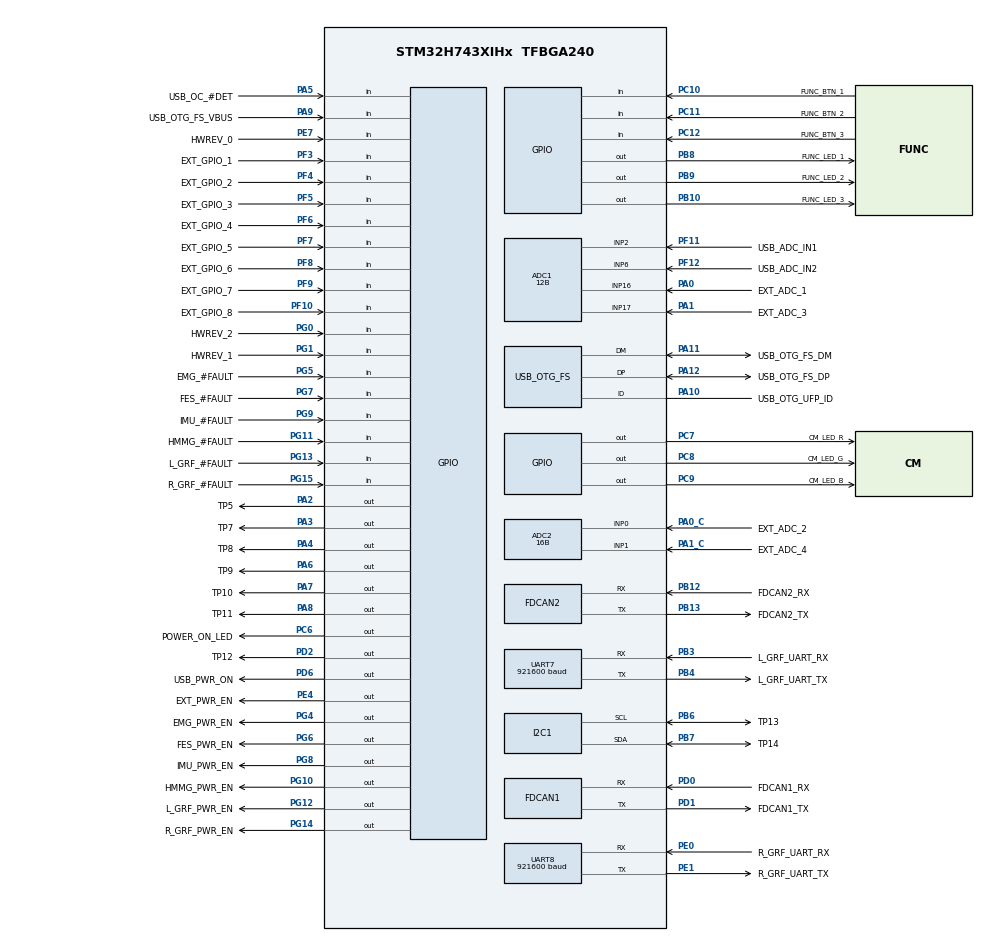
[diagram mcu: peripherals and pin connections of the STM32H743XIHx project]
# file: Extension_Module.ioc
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ADC1.Channel-0\#ChannelRegularConversion=ADC_CHANNEL_2
ADC1.Channel-1\#ChannelRegularConversion=ADC_CHANNEL_6
ADC1.Channel-4\#ChannelRegularConversion=ADC_CHANNEL_16
ADC1.Channel-5\#ChannelRegularConversion=ADC_CHANNEL_17
ADC1.ClockPrescaler=ADC_CLOCK_ASYNC_DIV4
ADC1.ContinuousConvMode=DISABLE
ADC1.ConversionDataManagement=ADC_CONVERSIONDATA_DMA_CIRCULAR
ADC1.EOCSelection=ADC_EOC_SEQ_CONV
ADC1.ExternalTrigConv=ADC_EXTERNALTRIG_T2_TRGO
ADC1.NbrOfConversion=4
ADC1.NbrOfConversionFlag=1
ADC1.OffsetNumber-0\#ChannelRegularConversion=ADC_OFFSET_NONE
ADC1.OffsetNumber-1\#ChannelRegularConversion=ADC_OFFSET_NONE
ADC1.OffsetNumber-4\#ChannelRegularConversion=ADC_OFFSET_NONE
ADC1.OffsetNumber-5\#ChannelRegularConversion=ADC_OFFSET_NONE
ADC1.OffsetSignedSaturation-0\#ChannelRegularConversion=DISABLE
ADC1.OffsetSignedSaturation-1\#ChannelRegularConversion=DISABLE
ADC1.Overrun=ADC_OVR_DATA_OVERWRITTEN
ADC1.Rank-0\#ChannelRegularConversion=1
ADC1.Rank-1\#ChannelRegularConversion=2
ADC1.Rank-4\#ChannelRegularConversion=3
ADC1.Rank-5\#ChannelRegularConversion=4
ADC1.Resolution=ADC_RESOLUTION_12B
ADC1.SamplingTime-0\#ChannelRegularConversion=ADC_SAMPLETIME_810CYCLES_5
ADC1.SamplingTime-1\#ChannelRegularConversion=ADC_SAMPLETIME_810CYCLES_5
ADC1.SamplingTime-4\#ChannelRegularConversion=ADC_SAMPLETIME_387CYCLES_5
ADC1.SamplingTime-5\#ChannelRegularConversion=ADC_SAMPLETIME_387CYCLES_5
ADC1.master=1
ADC2.Channel-0\#ChannelRegularConversion=ADC_CHANNEL_0
ADC2.Channel-1\#ChannelRegularConversion=ADC_CHANNEL_1
ADC2.ClockPrescaler=ADC_CLOCK_ASYNC_DIV4
ADC2.ContinuousConvMode=DISABLE
ADC2.ConversionDataManagement=ADC_CONVERSIONDATA_DMA_CIRCULAR
ADC2.EOCSelection=ADC_EOC_SEQ_CONV
ADC2.ExternalTrigConv=ADC_EXTERNALTRIG_T2_TRGO
ADC2.NbrOfConversion=2
ADC2.NbrOfConversionFlag=1
ADC2.OffsetNumber-0\#ChannelRegularConversion=ADC_OFFSET_NONE
ADC2.OffsetNumber-1\#ChannelRegularConversion=ADC_OFFSET_NONE
ADC2.OffsetSignedSaturation-0\#ChannelRegularConversion=DISABLE
ADC2.OffsetSignedSaturation-1\#ChannelRegularConversion=DISABLE
ADC2.Overrun=ADC_OVR_DATA_OVERWRITTEN
ADC2.Rank-0\#ChannelRegularConversion=1
ADC2.Rank-1\#ChannelRegularConversion=2
ADC2.Resolution=ADC_RESOLUTION_16B
ADC2.SamplingTime-0\#ChannelRegularConversion=ADC_SAMPLETIME_387CYCLES_5
ADC2.SamplingTime-1\#ChannelRegularConversion=ADC_SAMPLETIME_387CYCLES_5
CORTEX_M7.AccessPermission-Cortex_Memory_Protection_Unit_Region0_Settings=MPU_REGION_FULL_ACCESS
CORTEX_M7.AccessPermission-Cortex_Memory_Protection_Unit_Region1_Settings=MPU_REGION_FULL_ACCESS
CORTEX_M7.AccessPermission-Cortex_Memory_Protection_Unit_Region2_Settings=MPU_REGION_FULL_ACCESS
CORTEX_M7.BaseAddress-Cortex_Memory_Protection_Unit_Region0_Settings=0x30000000
CORTEX_M7.BaseAddress-Cortex_Memory_Protection_Unit_Region1_Settings=0x30040000
CORTEX_M7.BaseAddress-Cortex_Memory_Protection_Unit_Region2_Settings=0x38000000
CORTEX_M7.CPU_DCache=Enabled
CORTEX_M7.CPU_ICache=Enabled
CORTEX_M7.DisableExec-Cortex_Memory_Protection_Unit_Region0_Settings=MPU_INSTRUCTION_ACCESS_DISABLE
CORTEX_M7.DisableExec-Cortex_Memory_Protection_Unit_Region1_Settings=MPU_INSTRUCTION_ACCESS_DISABLE
CORTEX_M7.DisableExec-Cortex_Memory_Protection_Unit_Region2_Settings=MPU_INSTRUCTION_ACCESS_DISABLE
CORTEX_M7.Enable-Cortex_Memory_Protection_Unit_Region0_Settings=MPU_REGION_ENABLE
CORTEX_M7.Enable-Cortex_Memory_Protection_Unit_Region1_Settings=MPU_REGION_ENABLE
CORTEX_M7.Enable-Cortex_Memory_Protection_Unit_Region2_Settings=MPU_REGION_ENABLE
CORTEX_M7.IsBufferable-Cortex_Memory_Protection_Unit_Region0_Settings=MPU_ACCESS_NOT_BUFFERABLE
CORTEX_M7.IsCacheable-Cortex_Memory_Protection_Unit_Region0_Settings=MPU_ACCESS_NOT_CACHEABLE
CORTEX_M7.IsShareable-Cortex_Memory_Protection_Unit_Region0_Settings=MPU_ACCESS_SHAREABLE
CORTEX_M7.IsShareable-Cortex_Memory_Protection_Unit_Region1_Settings=MPU_ACCESS_SHAREABLE
CORTEX_M7.IsShareable-Cortex_Memory_Protection_Unit_Region2_Settings=MPU_ACCESS_SHAREABLE
CORTEX_M7.MPU_Control=MPU_HFNMI_PRIVDEF
CORTEX_M7.Size-Cortex_Memory_Protection_Unit_Region0_Settings=MPU_REGION_SIZE_256KB
CORTEX_M7.Size-Cortex_Memory_Protection_Unit_Region1_Settings=MPU_REGION_SIZE_32KB
CORTEX_M7.Size-Cortex_Memory_Protection_Unit_Region2_Settings=MPU_REGION_SIZE_64KB
CORTEX_M7.TypeExtField-Cortex_Memory_Protection_Unit_Region0_Settings=MPU_TEX_LEVEL1
CORTEX_M7.TypeExtField-Cortex_Memory_Protection_Unit_Region1_Settings=MPU_TEX_LEVEL1
CORTEX_M7.TypeExtField-Cortex_Memory_Protection_Unit_Region2_Settings=MPU_TEX_LEVEL1
Dma.ADC1.0.Direction=DMA_PERIPH_TO_MEMORY
Dma.ADC1.0.EventEnable=DISABLE
Dma.ADC1.0.FIFOMode=DMA_FIFOMODE_DISABLE
Dma.ADC1.0.Instance=DMA1_Stream0
Dma.ADC1.0.MemDataAlignment=DMA_MDATAALIGN_HALFWORD
Dma.ADC1.0.MemInc=DMA_MINC_ENABLE
Dma.ADC1.0.Mode=DMA_CIRCULAR
Dma.ADC1.0.PeriphDataAlignment=DMA_PDATAALIGN_HALFWORD
Dma.ADC1.0.PeriphInc=DMA_PINC_DISABLE
Dma.ADC1.0.Polarity=HAL_DMAMUX_REQ_GEN_RISING
Dma.ADC1.0.Priority=DMA_PRIORITY_LOW
Dma.ADC1.0.RequestNumber=1
Dma.ADC1.0.SignalID=NONE
Dma.ADC1.0.SyncEnable=DISABLE
Dma.ADC1.0.SyncPolarity=HAL_DMAMUX_SYNC_NO_EVENT
Dma.ADC1.0.SyncRequestNumber=1
Dma.ADC1.0.SyncSignalID=NONE
Dma.ADC2.3.Direction=DMA_PERIPH_TO_MEMORY
Dma.ADC2.3.EventEnable=DISABLE
Dma.ADC2.3.FIFOMode=DMA_FIFOMODE_DISABLE
Dma.ADC2.3.Instance=DMA1_Stream1
Dma.ADC2.3.MemDataAlignment=DMA_MDATAALIGN_HALFWORD
Dma.ADC2.3.MemInc=DMA_MINC_ENABLE
Dma.ADC2.3.Mode=DMA_CIRCULAR
Dma.ADC2.3.PeriphDataAlignment=DMA_PDATAALIGN_HALFWORD
Dma.ADC2.3.PeriphInc=DMA_PINC_DISABLE
Dma.ADC2.3.Polarity=HAL_DMAMUX_REQ_GEN_RISING
Dma.ADC2.3.Priority=DMA_PRIORITY_LOW
Dma.ADC2.3.RequestNumber=1
Dma.ADC2.3.SignalID=NONE
Dma.ADC2.3.SyncEnable=DISABLE
Dma.ADC2.3.SyncPolarity=HAL_DMAMUX_SYNC_NO_EVENT
Dma.ADC2.3.SyncRequestNumber=1
Dma.ADC2.3.SyncSignalID=NONE
Dma.Request0=ADC1
Dma.Request1=UART7_RX
Dma.Request2=UART8_RX
Dma.Request3=ADC2
Dma.UART7_RX.1.Direction=DMA_PERIPH_TO_MEMORY
Dma.UART7_RX.1.EventEnable=DISABLE
Dma.UART7_RX.1.FIFOMode=DMA_FIFOMODE_ENABLE
Dma.UART7_RX.1.FIFOThreshold=DMA_FIFO_THRESHOLD_1QUARTERFULL
Dma.UART7_RX.1.Instance=DMA1_Stream2
Dma.UART7_RX.1.MemBurst=DMA_MBURST_SINGLE
Dma.UART7_RX.1.MemDataAlignment=DMA_MDATAALIGN_BYTE
Dma.UART7_RX.1.MemInc=DMA_MINC_ENABLE
Dma.UART7_RX.1.Mode=DMA_CIRCULAR
Dma.UART7_RX.1.PeriphBurst=DMA_PBURST_SINGLE
Dma.UART7_RX.1.PeriphDataAlignment=DMA_PDATAALIGN_BYTE
Dma.UART7_RX.1.PeriphInc=DMA_PINC_DISABLE
Dma.UART7_RX.1.Polarity=HAL_DMAMUX_REQ_GEN_RISING
Dma.UART7_RX.1.Priority=DMA_PRIORITY_VERY_HIGH
Dma.UART7_RX.1.RequestNumber=1
Dma.UART7_RX.1.SignalID=NONE
Dma.UART7_RX.1.SyncEnable=DISABLE
Dma.UART7_RX.1.SyncPolarity=HAL_DMAMUX_SYNC_NO_EVENT
Dma.UART7_RX.1.SyncRequestNumber=1
Dma.UART7_RX.1.SyncSignalID=NONE
Dma.UART8_RX.2.Direction=DMA_PERIPH_TO_MEMORY
Dma.UART8_RX.2.EventEnable=DISABLE
Dma.UART8_RX.2.FIFOMode=DMA_FIFOMODE_ENABLE
Dma.UART8_RX.2.FIFOThreshold=DMA_FIFO_THRESHOLD_1QUARTERFULL
Dma.UART8_RX.2.Instance=DMA1_Stream3
Dma.UART8_RX.2.MemBurst=DMA_MBURST_SINGLE
Dma.UART8_RX.2.MemDataAlignment=DMA_MDATAALIGN_BYTE
Dma.UART8_RX.2.MemInc=DMA_MINC_ENABLE
Dma.UART8_RX.2.Mode=DMA_CIRCULAR
Dma.UART8_RX.2.PeriphBurst=DMA_PBURST_SINGLE
Dma.UART8_RX.2.PeriphDataAlignment=DMA_PDATAALIGN_BYTE
Dma.UART8_RX.2.PeriphInc=DMA_PINC_DISABLE
Dma.UART8_RX.2.Polarity=HAL_DMAMUX_REQ_GEN_RISING
Dma.UART8_RX.2.Priority=DMA_PRIORITY_VERY_HIGH
Dma.UART8_RX.2.RequestNumber=1
Dma.UART8_RX.2.SignalID=NONE
Dma.UART8_RX.2.SyncEnable=DISABLE
Dma.UART8_RX.2.SyncPolarity=HAL_DMAMUX_SYNC_NO_EVENT
Dma.UART8_RX.2.SyncRequestNumber=1
Dma.UART8_RX.2.SyncSignalID=NONE
FATFS._FS_RPATH=0
FATFS._MAX_SS=4096
FATFS._USE_LFN=2
FDCAN1.AutoRetransmission=ENABLE
FDCAN1.CalculateBaudRateNominal=1000000
FDCAN1.CalculateTimeBitNominal=1000
FDCAN1.CalculateTimeQuantumNominal=125.0
FDCAN1.DataSyncJumpWidth=4
FDCAN1.DataTimeSeg1=11
FDCAN1.DataTimeSeg2=4
FDCAN1.FrameFormat=FDCAN_FRAME_FD_BRS
FDCAN1.NominalPrescaler=10
FDCAN1.NominalSyncJumpWidth=2
FDCAN1.NominalTimeSeg1=5
FDCAN1.NominalTimeSeg2=2
FDCAN1.RxBufferSize=FDCAN_DATA_BYTES_64
FDCAN1.RxBuffersNbr=0
FDCAN1.RxFifo0ElmtSize=FDCAN_DATA_BYTES_64
FDCAN1.RxFifo0ElmtsNbr=20
FDCAN1.RxFifo1ElmtSize=FDCAN_DATA_BYTES_64
FDCAN1.RxFifo1ElmtsNbr=0
FDCAN1.StdFiltersNbr=28
FDCAN1.TransmitPause=ENABLE
FDCAN1.TxBuffersNbr=0
FDCAN1.TxElmtSize=FDCAN_DATA_BYTES_64
FDCAN1.TxEventsNbr=0
FDCAN1.TxFifoQueueElmtsNbr=32
FDCAN1.TxFifoQueueMode=FDCAN_TX_QUEUE_OPERATION
FDCAN2.AutoRetransmission=ENABLE
FDCAN2.CalculateBaudRateNominal=1000000
FDCAN2.CalculateTimeBitNominal=1000
FDCAN2.CalculateTimeQuantumNominal=125.0
FDCAN2.DataSyncJumpWidth=4
FDCAN2.DataTimeSeg1=11
FDCAN2.DataTimeSeg2=4
FDCAN2.FrameFormat=FDCAN_FRAME_FD_BRS
FDCAN2.MessageRAMOffset=1280
FDCAN2.NominalPrescaler=10
FDCAN2.NominalSyncJumpWidth=2
FDCAN2.NominalTimeSeg1=5
FDCAN2.NominalTimeSeg2=2
FDCAN2.RxBufferSize=FDCAN_DATA_BYTES_64
FDCAN2.RxFifo0ElmtSize=FDCAN_DATA_BYTES_64
FDCAN2.RxFifo0ElmtsNbr=20
FDCAN2.RxFifo1ElmtSize=FDCAN_DATA_BYTES_64
FDCAN2.StdFiltersNbr=28
FDCAN2.TransmitPause=ENABLE
FDCAN2.TxElmtSize=FDCAN_DATA_BYTES_64
FDCAN2.TxFifoQueueElmtsNbr=32
FDCAN2.TxFifoQueueMode=FDCAN_TX_QUEUE_OPERATION
FREERTOS.HEAP_NUMBER=4
FREERTOS.Tasks01=DefaultTask,8,128,StartDefaultTask,Default,NULL,Dynamic,NULL,NULL;UserTask,54,8192,StartUserTask,As weak,NULL,Dynamic,NULL,NULL;StartupTask,55,128,StartStartupTask,As weak,NULL,Dynamic,NULL,NULL
FREERTOS.configCHECK_FOR_STACK_OVERFLOW=2
FREERTOS.configENABLE_FPU=1
FREERTOS.configTOTAL_HEAP_SIZE=131072
FREERTOS.configUSE_NEWLIB_REENTRANT=1
I2C1.Timing=0x307075B1
Mcu.Family=STM32H7
Mcu.Name=STM32H743XIHx
Mcu.Package=TFBGA240
NVIC.ADC_IRQn=true\:5\:0\:false\:false\:true\:true\:true\:true\:true
NVIC.DMA1_Stream0_IRQn=true\:5\:0\:true\:false\:true\:true\:false\:true\:true
NVIC.DMA1_Stream1_IRQn=true\:5\:0\:true\:false\:true\:true\:false\:true\:true
NVIC.DMA1_Stream2_IRQn=true\:5\:0\:true\:false\:true\:true\:false\:true\:true
NVIC.DMA1_Stream3_IRQn=true\:5\:0\:true\:false\:true\:false\:false\:true\:true
NVIC.FDCAN1_IT0_IRQn=true\:5\:0\:true\:false\:true\:true\:true\:true\:true
NVIC.FDCAN1_IT1_IRQn=true\:5\:0\:false\:false\:true\:true\:true\:true\:true
NVIC.FDCAN2_IT0_IRQn=true\:5\:0\:false\:false\:true\:true\:true\:true\:true
NVIC.FDCAN2_IT1_IRQn=true\:5\:0\:false\:false\:true\:true\:true\:true\:true
NVIC.PriorityGroup=NVIC_PRIORITYGROUP_4
NVIC.TIM1_UP_IRQn=true\:15\:0\:false\:false\:true\:false\:false\:true\:true
NVIC.TimeBase=TIM1_UP_IRQn
NVIC.TimeBaseIP=TIM1
NVIC.UART7_IRQn=true\:5\:0\:false\:false\:true\:true\:true\:true\:true
NVIC.UART8_IRQn=true\:5\:0\:false\:false\:true\:true\:true\:true\:true
PA0.GPIO_Label=EXT_ADC_1
PA0.Mode=IN16-Single-Ended
PA0.Signal=ADC1_INP16
PA0_C.GPIO_Label=EXT_ADC_2
PA0_C.Signal=ADCx_INP0
PA1.GPIO_Label=EXT_ADC_3
PA1.Mode=IN17-Single-Ended
PA1.Signal=ADC1_INP17
PA10.GPIO_Label=USB_OTG_UFP_ID
PA10.Mode=OTG/Dual_Role_Device
PA10.Signal=USB_OTG_FS_ID
PA11.GPIO_Label=USB_OTG_FS_DM
PA11.GPIO_PuPd=GPIO_NOPULL
PA11.GPIO_Speed=GPIO_SPEED_FREQ_VERY_HIGH
PA11.Mode=OTG/Dual_Role_Device
PA11.Signal=USB_OTG_FS_DM
PA12.GPIO_Label=USB_OTG_FS_DP
PA12.GPIO_PuPd=GPIO_NOPULL
PA12.GPIO_Speed=GPIO_SPEED_FREQ_VERY_HIGH
PA12.Mode=OTG/Dual_Role_Device
PA12.Signal=USB_OTG_FS_DP
PA13\ (JTMS/SWDIO).GPIO_Label=DEBUG_SWDIO
PA13\ (JTMS/SWDIO).Mode=Serial_Wire
PA13\ (JTMS/SWDIO).Signal=DEBUG_JTMS-SWDIO
PA14\ (JTCK/SWCLK).GPIO_Label=DEBUG_SWCLK
PA14\ (JTCK/SWCLK).Mode=Serial_Wire
PA14\ (JTCK/SWCLK).Signal=DEBUG_JTCK-SWCLK
PA1_C.GPIO_Label=EXT_ADC_4
PA1_C.Signal=ADCx_INP1
PA2.GPIO_Label=TP5
PA2.GPIO_PuPd=GPIO_PULLDOWN
PA2.Signal=GPIO_Output
PA3.GPIO_Label=TP7
PA3.GPIO_PuPd=GPIO_PULLDOWN
PA3.Signal=GPIO_Output
PA4.GPIO_Label=TP8
PA4.Signal=GPIO_Output
PA5.GPIO_Label=USB_OC_\#DET
PA5.GPIO_PuPd=GPIO_NOPULL
PA5.Signal=GPIO_Input
PA6.GPIO_Label=TP9
PA6.GPIO_PuPd=GPIO_PULLDOWN
PA6.Signal=GPIO_Output
PA7.GPIO_Label=TP10
PA7.GPIO_PuPd=GPIO_PULLDOWN
PA7.Signal=GPIO_Output
PA8.GPIO_Label=TP11
PA8.GPIO_PuPd=GPIO_PULLDOWN
PA8.Signal=GPIO_Output
PA9.GPIO_Label=USB_OTG_FS_VBUS
PA9.GPIO_PuPd=GPIO_PULLUP
PA9.Signal=GPIO_Input
PB10.GPIO_Label=FUNC_LED_3
PB10.Signal=GPIO_Output
PB12.GPIO_Label=FDCAN2_RX
PB12.Mode=FDCAN_Activate
PB12.Signal=FDCAN2_RX
PB13.GPIO_Label=FDCAN2_TX
PB13.Mode=FDCAN_Activate
PB13.Signal=FDCAN2_TX
PB3\ (JTDO/TRACESWO).GPIO_Label=L_GRF_UART_RX
PB3\ (JTDO/TRACESWO).Mode=Asynchronous
PB3\ (JTDO/TRACESWO).Signal=UART7_RX
PB4\ (NJTRST).GPIO_Label=L_GRF_UART_TX
PB4\ (NJTRST).Mode=Asynchronous
PB4\ (NJTRST).Signal=UART7_TX
PB6.GPIO_Label=TP13
PB6.Mode=I2C
PB6.Signal=I2C1_SCL
PB7.GPIO_Label=TP14
PB7.Mode=I2C
PB7.Signal=I2C1_SDA
PB8.GPIO_Label=FUNC_LED_1
PB8.Signal=GPIO_Output
PB9.GPIO_Label=FUNC_LED_2
PB9.Signal=GPIO_Output
PC10.GPIO_Label=FUNC_BTN_1
PC10.Signal=GPIO_Input
PC11.GPIO_Label=FUNC_BTN_2
PC11.Signal=GPIO_Input
PC12.GPIO_Label=FUNC_BTN_3
PC12.Signal=GPIO_Input
PC14-OSC32_IN\ (OSC32_IN).Mode=LSE-External-Oscillator
PC14-OSC32_IN\ (OSC32_IN).Signal=RCC_OSC32_IN
PC15-OSC32_OUT\ (OSC32_OUT).Mode=LSE-External-Oscillator
PC15-OSC32_OUT\ (OSC32_OUT).Signal=RCC_OSC32_OUT
PC6.GPIO_Label=POWER_ON_LED
PC6.Signal=GPIO_Output
PC7.GPIO_Label=CM_LED_R
PC7.Signal=GPIO_Output
PC8.GPIO_Label=CM_LED_G
PC8.Signal=GPIO_Output
PC9.GPIO_Label=CM_LED_B
PC9.Signal=GPIO_Output
PD0.GPIO_Label=FDCAN1_RX
PD0.Mode=FDCAN_Activate
PD0.Signal=FDCAN1_RX
PD1.GPIO_Label=FDCAN1_TX
PD1.Mode=FDCAN_Activate
PD1.Signal=FDCAN1_TX
PD2.GPIO_Label=TP12
PD2.GPIO_PuPd=GPIO_PULLDOWN
PD2.Signal=GPIO_Output
PD6.GPIO_Label=USB_PWR_ON
PD6.GPIO_PuPd=GPIO_PULLUP
PD6.GPIO_Speed=GPIO_SPEED_FREQ_VERY_HIGH
PD6.Signal=GPIO_Output
PE0.GPIO_Label=R_GRF_UART_RX
PE0.Mode=Asynchronous
PE0.Signal=UART8_RX
PE1.GPIO_Label=R_GRF_UART_TX
PE1.Mode=Asynchronous
PE1.Signal=UART8_TX
PE4.GPIO_Label=EXT_PWR_EN
PE4.Signal=GPIO_Output
PE7.GPIO_Label=HWREV_0
PE7.Signal=GPIO_Input
PF10.GPIO_Label=EXT_GPIO_8
PF10.GPIO_PuPd=GPIO_NOPULL
PF10.Signal=GPIO_Input
PF11.GPIO_Label=USB_ADC_IN1
PF11.Mode=IN2-Single-Ended
PF11.Signal=ADC1_INP2
PF12.GPIO_Label=USB_ADC_IN2
PF12.Mode=IN6-Single-Ended
PF12.Signal=ADC1_INP6
PF3.GPIO_Label=EXT_GPIO_1
PF3.GPIO_PuPd=GPIO_NOPULL
PF3.Signal=GPIO_Input
PF4.GPIO_Label=EXT_GPIO_2
PF4.GPIO_PuPd=GPIO_NOPULL
PF4.Signal=GPIO_Input
PF5.GPIO_Label=EXT_GPIO_3
PF5.GPIO_PuPd=GPIO_NOPULL
PF5.Signal=GPIO_Input
PF6.GPIO_Label=EXT_GPIO_4
PF6.GPIO_PuPd=GPIO_NOPULL
PF6.Signal=GPIO_Input
PF7.GPIO_Label=EXT_GPIO_5
PF7.GPIO_PuPd=GPIO_NOPULL
PF7.Signal=GPIO_Input
PF8.GPIO_Label=EXT_GPIO_6
PF8.GPIO_PuPd=GPIO_NOPULL
PF8.Signal=GPIO_Input
PF9.GPIO_Label=EXT_GPIO_7
PF9.GPIO_PuPd=GPIO_NOPULL
PF9.Signal=GPIO_Input
PG0.GPIO_Label=HWREV_2
PG0.Signal=GPIO_Input
PG1.GPIO_Label=HWREV_1
PG1.Signal=GPIO_Input
PG10.GPIO_Label=HMMG_PWR_EN
PG10.Signal=GPIO_Output
PG11.GPIO_Label=HMMG_\#FAULT
PG11.Signal=GPIO_Input
PG12.GPIO_Label=L_GRF_PWR_EN
PG12.Signal=GPIO_Output
PG13.GPIO_Label=L_GRF_\#FAULT
PG13.Signal=GPIO_Input
PG14.GPIO_Label=R_GRF_PWR_EN
PG14.Signal=GPIO_Output
PG15.GPIO_Label=R_GRF_\#FAULT
PG15.Signal=GPIO_Input
PG4.GPIO_Label=EMG_PWR_EN
PG4.Signal=GPIO_Output
PG5.GPIO_Label=EMG_\#FAULT
PG5.Signal=GPIO_Input
PG6.GPIO_Label=FES_PWR_EN
PG6.Signal=GPIO_Output
PG7.GPIO_Label=FES_\#FAULT
PG7.Signal=GPIO_Input
PG8.GPIO_Label=IMU_PWR_EN
PG8.Signal=GPIO_Output
PG9.GPIO_Label=IMU_\#FAULT
PG9.Signal=GPIO_Input
PH0-OSC_IN\ (PH0).Mode=HSE-External-Oscillator
PH0-OSC_IN\ (PH0).Signal=RCC_OSC_IN
PH1-OSC_OUT\ (PH1).Mode=HSE-External-Oscillator
PH1-OSC_OUT\ (PH1).Signal=RCC_OSC_OUT
ProjectManager.HeapSize=0x2000
ProjectManager.StackSize=0x2000
ProjectManager.TargetToolchain=CMake
RCC.ADCFreq_Value=80000000
RCC.APB1Freq_Value=120000000
RCC.APB2Freq_Value=120000000
RCC.APB3Freq_Value=120000000
RCC.APB4Freq_Value=120000000
RCC.CKPERSourceSelection=RCC_CLKPSOURCE_HSE
RCC.CortexFreq_Value=480000000
RCC.D1PPRE=RCC_APB3_DIV2
RCC.D2PPRE1=RCC_APB1_DIV2
RCC.D2PPRE2=RCC_APB2_DIV2
RCC.D3PPRE=RCC_APB4_DIV2
RCC.DIVM1=5
RCC.DIVM2=5
RCC.DIVM3=5
RCC.DIVN1=192
RCC.DIVN2=80
RCC.DIVN3=192
RCC.DIVP2=5
RCC.DIVQ1=12
RCC.DIVQ3=20
RCC.DIVR2=1
RCC.DIVR3=10
RCC.HCLKFreq_Value=240000000
RCC.HPRE=RCC_HCLK_DIV2
RCC.PLL1_VCO_SEL-AdvancedSettings=RCC_PLL1VCOMEDIUM
RCC.PLL2FRACN=0
RCC.PLL2_VCI_Range-AdvancedSettings=RCC_PLL2VCIRANGE_1
RCC.PLL3_VCO_SEL-AdvancedSettings=RCC_PLL3VCOMEDIUM
RCC.PLLFRACN=0
RCC.PLLSourceVirtual=RCC_PLLSOURCE_HSE
RCC.SYSCLKFreq_VALUE=480000000
RCC.SYSCLKSource=RCC_SYSCLKSOURCE_PLLCLK
RCC.SupplySource=PWR_LDO_SUPPLY
RCC.USBCLockSelection=RCC_USBCLKSOURCE_HSI48
RCC.USBFreq_Value=48000000
SH.ADCx_INP0.0=ADC2_INP0,IN0-Single-Ended
SH.ADCx_INP1.0=ADC2_INP1,IN1-Single-Ended
TIM2.AutoReloadPreload=TIM_AUTORELOAD_PRELOAD_ENABLE
TIM2.Period=100-1
TIM2.Prescaler=240-1
TIM2.TIM_MasterOutputTrigger=TIM_TRGO_UPDATE
UART7.BaudRate=921600
UART7.FIFOMode=FIFOMODE_ENABLE
UART7.OverrunDisableParam=UART_ADVFEATURE_OVERRUN_ENABLE
UART7.RXFIFOThreshold=RXFIFO_THRESHOLD_1QUARTERFULL
UART7.TXFIFOThreshold=TXFIFO_THRESHOLD_1QUARTERFULL
UART8.BaudRate=921600
UART8.FIFOMode=FIFOMODE_ENABLE
UART8.OverrunDisableParam=UART_ADVFEATURE_OVERRUN_ENABLE
UART8.RXFIFOThreshold=RXFIFO_THRESHOLD_1QUARTERFULL
UART8.TXFIFOThreshold=TXFIFO_THRESHOLD_1QUARTERFULL
VP_FATFS_VS_Generic.Mode=User_defined
VP_FREERTOS_VS_CMSIS_V2.Mode=CMSIS_V2
VP_MEMORYMAP_VS_MEMORYMAP.Mode=CurAppReg
VP_SYS_VS_tim1.Mode=TIM1
VP_TIM2_VS_ClockSourceINT.Mode=Internal
board=custom

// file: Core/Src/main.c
/* USER CODE BEGIN Header */
/**
  ******************************************************************************
  * @file           : main.c
  * @brief          : Main program body
  ******************************************************************************
  * @attention
  *
  * Copyright (c) 2025 STMicroelectronics.
  * All rights reserved.
  *
  * This software is licensed under terms that can be found in the LICENSE file
  * in the root directory of this software component.
  * If no LICENSE file comes with this software, it is provided AS-IS.
  *
  ******************************************************************************
  */
/* USER CODE END Header */
#include "main.h"
#include "cmsis_os.h"
#include "fatfs.h"

ADC_HandleTypeDef hadc1;
ADC_HandleTypeDef hadc2;
DMA_HandleTypeDef hdma_adc1;
DMA_HandleTypeDef hdma_adc2;

FDCAN_HandleTypeDef hfdcan1;
FDCAN_HandleTypeDef hfdcan2;

I2C_HandleTypeDef hi2c1;

TIM_HandleTypeDef htim2;

UART_HandleTypeDef huart7;
UART_HandleTypeDef huart8;
DMA_HandleTypeDef hdma_uart7_rx;
DMA_HandleTypeDef hdma_uart8_rx;

/* Definitions for DefaultTask */
osThreadId_t DefaultTaskHandle;
const osThreadAttr_t DefaultTask_attributes = {
  .name = "DefaultTask",
  .stack_size = 128 * 4,
  .priority = (osPriority_t) osPriorityLow,
};
/* Definitions for UserTask */
osThreadId_t UserTaskHandle;
const osThreadAttr_t UserTask_attributes = {
  .name = "UserTask",
  .stack_size = 8192 * 4,
  .priority = (osPriority_t) osPriorityRealtime6,
};
/* Definitions for StartupTask */
osThreadId_t StartupTaskHandle;
const osThreadAttr_t StartupTask_attributes = {
  .name = "StartupTask",
  .stack_size = 128 * 4,
  .priority = (osPriority_t) osPriorityRealtime7,
};

void SystemClock_Config(void);
void PeriphCommonClock_Config(void);
static void MPU_Config(void);
static void MX_GPIO_Init(void);
static void MX_DMA_Init(void);
static void MX_I2C1_Init(void);
static void MX_UART7_Init(void);
static void MX_UART8_Init(void);
static void MX_FDCAN1_Init(void);
static void MX_USB_OTG_FS_USB_Init(void);
static void MX_ADC1_Init(void);
static void MX_ADC2_Init(void);
static void MX_FDCAN2_Init(void);
static void MX_TIM2_Init(void);
void StartDefaultTask(void *argument);
void StartUserTask(void *argument);
void StartStartupTask(void *argument);

/* USER CODE BEGIN 0 */
// static AGRBStatusDef _debug_adc_assign;
// static AGRBStatusDef _debug_uart7_status;
// static AGRBStatusDef _debug_uart8_status;
// TaskUSBControlTask_Init_t usbControlInitStruct;
/* USER CODE END 0 */

int main(void)
{

  /* MPU Configuration--------------------------------------------------------*/
  MPU_Config();

  /* Enable the CPU Cache */

  /* Enable I-Cache---------------------------------------------------------*/
  SCB_EnableICache();

  /* Enable D-Cache---------------------------------------------------------*/
  SCB_EnableDCache();

  /* MCU Configuration--------------------------------------------------------*/

  /* Reset of all peripherals, Initializes the Flash interface and the Systick. */
  HAL_Init();

  /* Configure the system clock */
  SystemClock_Config();

  /* Configure the peripherals common clocks */
  PeriphCommonClock_Config();

  /* Initialize all configured peripherals */
  MX_GPIO_Init();
  MX_DMA_Init();
  MX_I2C1_Init();
  MX_UART7_Init();
  MX_UART8_Init();
  MX_FATFS_Init();
  MX_FDCAN1_Init();
  MX_USB_OTG_FS_USB_Init();
  MX_ADC1_Init();
  MX_ADC2_Init();
  MX_FDCAN2_Init();
  MX_TIM2_Init();

  /* Init scheduler */
  osKernelInitialize();

  /* Create the thread(s) */
  /* creation of DefaultTask */
  DefaultTaskHandle = osThreadNew(StartDefaultTask, NULL, &DefaultTask_attributes);

  /* creation of UserTask */
  UserTaskHandle = osThreadNew(StartUserTask, NULL, &UserTask_attributes);

  /* creation of StartupTask */
  StartupTaskHandle = osThreadNew(StartStartupTask, NULL, &StartupTask_attributes);

  /* USER CODE BEGIN RTOS_THREADS */
  /* add threads, ... */

  /* [CRITICAL] UserTask Priority Override ⭐ KING
   * - IOC 설정값(Realtime4)을 Realtime6으로 상향
   * - 제어 공학적 원칙: Main Control Loop가 최우선
   * - FDCAN Rx Task(Realtime4)보다 높아야 함
   */
  osThreadSetPriority(UserTaskHandle, osPriorityRealtime6);

  osThreadSuspend(DefaultTaskHandle);
  osThreadSuspend(UserTaskHandle);
  /* USER CODE END RTOS_THREADS */

  /* Start scheduler */
  osKernelStart();

  /* We should never get here as control is now taken by the scheduler */

  /* Infinite loop */
  while (1)
  {

  }
}

void SystemClock_Config(void)
{
  RCC_OscInitTypeDef RCC_OscInitStruct = {0};
  RCC_ClkInitTypeDef RCC_ClkInitStruct = {0};

  /** Supply configuration update enable
  */
  HAL_PWREx_ConfigSupply(PWR_LDO_SUPPLY);

  /** Configure the main internal regulator output voltage
  */
  __HAL_PWR_VOLTAGESCALING_CONFIG(PWR_REGULATOR_VOLTAGE_SCALE0);

  while(!__HAL_PWR_GET_FLAG(PWR_FLAG_VOSRDY)) {}

  /** Initializes the RCC Oscillators according to the specified parameters
  * in the RCC_OscInitTypeDef structure.
  */
  RCC_OscInitStruct.OscillatorType = RCC_OSCILLATORTYPE_HSI48|RCC_OSCILLATORTYPE_HSE;
  RCC_OscInitStruct.HSEState = RCC_HSE_ON;
  RCC_OscInitStruct.HSI48State = RCC_HSI48_ON;
  RCC_OscInitStruct.PLL.PLLState = RCC_PLL_ON;
  RCC_OscInitStruct.PLL.PLLSource = RCC_PLLSOURCE_HSE;
  RCC_OscInitStruct.PLL.PLLM = 5;
  RCC_OscInitStruct.PLL.PLLN = 192;
  RCC_OscInitStruct.PLL.PLLP = 2;
  RCC_OscInitStruct.PLL.PLLQ = 12;
  RCC_OscInitStruct.PLL.PLLR = 2;
  RCC_OscInitStruct.PLL.PLLRGE = RCC_PLL1VCIRANGE_2;
  RCC_OscInitStruct.PLL.PLLVCOSEL = RCC_PLL1VCOWIDE;
  RCC_OscInitStruct.PLL.PLLFRACN = 0;
  if (HAL_RCC_OscConfig(&RCC_OscInitStruct) != HAL_OK)
  {
    Error_Handler();
  }

  /** Initializes the CPU, AHB and APB buses clocks
  */
  RCC_ClkInitStruct.ClockType = RCC_CLOCKTYPE_HCLK|RCC_CLOCKTYPE_SYSCLK
                              |RCC_CLOCKTYPE_PCLK1|RCC_CLOCKTYPE_PCLK2
                              |RCC_CLOCKTYPE_D3PCLK1|RCC_CLOCKTYPE_D1PCLK1;
  RCC_ClkInitStruct.SYSCLKSource = RCC_SYSCLKSOURCE_PLLCLK;
  RCC_ClkInitStruct.SYSCLKDivider = RCC_SYSCLK_DIV1;
  RCC_ClkInitStruct.AHBCLKDivider = RCC_HCLK_DIV2;
  RCC_ClkInitStruct.APB3CLKDivider = RCC_APB3_DIV2;
  RCC_ClkInitStruct.APB1CLKDivider = RCC_APB1_DIV2;
  RCC_ClkInitStruct.APB2CLKDivider = RCC_APB2_DIV2;
  RCC_ClkInitStruct.APB4CLKDivider = RCC_APB4_DIV2;

  if (HAL_RCC_ClockConfig(&RCC_ClkInitStruct, FLASH_LATENCY_4) != HAL_OK)
  {
    Error_Handler();
  }
}

void PeriphCommonClock_Config(void)
{
  RCC_PeriphCLKInitTypeDef PeriphClkInitStruct = {0};

  /** Initializes the peripherals clock
  */
  PeriphClkInitStruct.PeriphClockSelection = RCC_PERIPHCLK_ADC;
  PeriphClkInitStruct.PLL2.PLL2M = 5;
  PeriphClkInitStruct.PLL2.PLL2N = 80;
  PeriphClkInitStruct.PLL2.PLL2P = 5;
  PeriphClkInitStruct.PLL2.PLL2Q = 2;
  PeriphClkInitStruct.PLL2.PLL2R = 1;
  PeriphClkInitStruct.PLL2.PLL2RGE = RCC_PLL2VCIRANGE_2;
  PeriphClkInitStruct.PLL2.PLL2VCOSEL = RCC_PLL2VCOWIDE;
  PeriphClkInitStruct.PLL2.PLL2FRACN = 0;
  PeriphClkInitStruct.AdcClockSelection = RCC_ADCCLKSOURCE_PLL2;
  if (HAL_RCCEx_PeriphCLKConfig(&PeriphClkInitStruct) != HAL_OK)
  {
    Error_Handler();
  }
}

static void MX_ADC1_Init(void)
{

  ADC_MultiModeTypeDef multimode = {0};
  ADC_ChannelConfTypeDef sConfig = {0};

  /** Common config
  */
  hadc1.Instance = ADC1;
  hadc1.Init.ClockPrescaler = ADC_CLOCK_ASYNC_DIV4;
  hadc1.Init.Resolution = ADC_RESOLUTION_12B;
  hadc1.Init.ScanConvMode = ADC_SCAN_ENABLE;
  hadc1.Init.EOCSelection = ADC_EOC_SEQ_CONV;
  hadc1.Init.LowPowerAutoWait = DISABLE;
  hadc1.Init.ContinuousConvMode = DISABLE;
  hadc1.Init.NbrOfConversion = 4;
  hadc1.Init.DiscontinuousConvMode = DISABLE;
  hadc1.Init.ExternalTrigConv = ADC_EXTERNALTRIG_T2_TRGO;
  hadc1.Init.ExternalTrigConvEdge = ADC_EXTERNALTRIGCONVEDGE_RISING;
  hadc1.Init.ConversionDataManagement = ADC_CONVERSIONDATA_DMA_CIRCULAR;
  hadc1.Init.Overrun = ADC_OVR_DATA_OVERWRITTEN;
  hadc1.Init.LeftBitShift = ADC_LEFTBITSHIFT_NONE;
  hadc1.Init.OversamplingMode = DISABLE;
  hadc1.Init.Oversampling.Ratio = 1;
  if (HAL_ADC_Init(&hadc1) != HAL_OK)
  {
    Error_Handler();
  }

  /** Configure the ADC multi-mode
  */
  multimode.Mode = ADC_MODE_INDEPENDENT;
  if (HAL_ADCEx_MultiModeConfigChannel(&hadc1, &multimode) != HAL_OK)
  {
    Error_Handler();
  }

  /** Configure Regular Channel
  */
  sConfig.Channel = ADC_CHANNEL_2;
  sConfig.Rank = ADC_REGULAR_RANK_1;
  sConfig.SamplingTime = ADC_SAMPLETIME_810CYCLES_5;
  sConfig.SingleDiff = ADC_SINGLE_ENDED;
  sConfig.OffsetNumber = ADC_OFFSET_NONE;
  sConfig.Offset = 0;
  sConfig.OffsetSignedSaturation = DISABLE;
  if (HAL_ADC_ConfigChannel(&hadc1, &sConfig) != HAL_OK)
  {
    Error_Handler();
  }

  /** Configure Regular Channel
  */
  sConfig.Channel = ADC_CHANNEL_6;
  sConfig.Rank = ADC_REGULAR_RANK_2;
  if (HAL_ADC_ConfigChannel(&hadc1, &sConfig) != HAL_OK)
  {
    Error_Handler();
  }

  /** Configure Regular Channel
  */
  sConfig.Channel = ADC_CHANNEL_16;
  sConfig.Rank = ADC_REGULAR_RANK_3;
  sConfig.SamplingTime = ADC_SAMPLETIME_387CYCLES_5;
  if (HAL_ADC_ConfigChannel(&hadc1, &sConfig) != HAL_OK)
  {
    Error_Handler();
  }

  /** Configure Regular Channel
  */
  sConfig.Channel = ADC_CHANNEL_17;
  sConfig.Rank = ADC_REGULAR_RANK_4;
  if (HAL_ADC_ConfigChannel(&hadc1, &sConfig) != HAL_OK)
  {
    Error_Handler();
  }

}

static void MX_ADC2_Init(void)
{

  ADC_ChannelConfTypeDef sConfig = {0};

  /** Common config
  */
  hadc2.Instance = ADC2;
  hadc2.Init.ClockPrescaler = ADC_CLOCK_ASYNC_DIV4;
  hadc2.Init.Resolution = ADC_RESOLUTION_16B;
  hadc2.Init.ScanConvMode = ADC_SCAN_ENABLE;
  hadc2.Init.EOCSelection = ADC_EOC_SEQ_CONV;
  hadc2.Init.LowPowerAutoWait = DISABLE;
  hadc2.Init.ContinuousConvMode = DISABLE;
  hadc2.Init.NbrOfConversion = 2;
  hadc2.Init.DiscontinuousConvMode = DISABLE;
  hadc2.Init.ExternalTrigConv = ADC_EXTERNALTRIG_T2_TRGO;
  hadc2.Init.ExternalTrigConvEdge = ADC_EXTERNALTRIGCONVEDGE_RISING;
  hadc2.Init.ConversionDataManagement = ADC_CONVERSIONDATA_DMA_CIRCULAR;
  hadc2.Init.Overrun = ADC_OVR_DATA_OVERWRITTEN;
  hadc2.Init.LeftBitShift = ADC_LEFTBITSHIFT_NONE;
  hadc2.Init.OversamplingMode = DISABLE;
  hadc2.Init.Oversampling.Ratio = 1;
  if (HAL_ADC_Init(&hadc2) != HAL_OK)
  {
    Error_Handler();
  }

  /** Configure Regular Channel
  */
  sConfig.Channel = ADC_CHANNEL_0;
  sConfig.Rank = ADC_REGULAR_RANK_1;
  sConfig.SamplingTime = ADC_SAMPLETIME_387CYCLES_5;
  sConfig.SingleDiff = ADC_SINGLE_ENDED;
  sConfig.OffsetNumber = ADC_OFFSET_NONE;
  sConfig.Offset = 0;
  sConfig.OffsetSignedSaturation = DISABLE;
  if (HAL_ADC_ConfigChannel(&hadc2, &sConfig) != HAL_OK)
  {
    Error_Handler();
  }

  /** Configure Regular Channel
  */
  sConfig.Channel = ADC_CHANNEL_1;
  sConfig.Rank = ADC_REGULAR_RANK_2;
  if (HAL_ADC_ConfigChannel(&hadc2, &sConfig) != HAL_OK)
  {
    Error_Handler();
  }

}

static void MX_FDCAN1_Init(void)
{

  hfdcan1.Instance = FDCAN1;
  hfdcan1.Init.FrameFormat = FDCAN_FRAME_FD_BRS;
  hfdcan1.Init.Mode = FDCAN_MODE_NORMAL;
  hfdcan1.Init.AutoRetransmission = ENABLE;
  hfdcan1.Init.TransmitPause = ENABLE;
  hfdcan1.Init.ProtocolException = DISABLE;
  hfdcan1.Init.NominalPrescaler = 10;
  hfdcan1.Init.NominalSyncJumpWidth = 2;
  hfdcan1.Init.NominalTimeSeg1 = 5;
  hfdcan1.Init.NominalTimeSeg2 = 2;
  hfdcan1.Init.DataPrescaler = 1;
  hfdcan1.Init.DataSyncJumpWidth = 4;
  hfdcan1.Init.DataTimeSeg1 = 11;
  hfdcan1.Init.DataTimeSeg2 = 4;
  hfdcan1.Init.MessageRAMOffset = 0;
  hfdcan1.Init.StdFiltersNbr = 28;
  hfdcan1.Init.ExtFiltersNbr = 0;
  hfdcan1.Init.RxFifo0ElmtsNbr = 20;
  hfdcan1.Init.RxFifo0ElmtSize = FDCAN_DATA_BYTES_64;
  hfdcan1.Init.RxFifo1ElmtsNbr = 0;
  hfdcan1.Init.RxFifo1ElmtSize = FDCAN_DATA_BYTES_64;
  hfdcan1.Init.RxBuffersNbr = 0;
  hfdcan1.Init.RxBufferSize = FDCAN_DATA_BYTES_64;
  hfdcan1.Init.TxEventsNbr = 0;
  hfdcan1.Init.TxBuffersNbr = 0;
  hfdcan1.Init.TxFifoQueueElmtsNbr = 32;
  hfdcan1.Init.TxFifoQueueMode = FDCAN_TX_QUEUE_OPERATION;
  hfdcan1.Init.TxElmtSize = FDCAN_DATA_BYTES_64;
  if (HAL_FDCAN_Init(&hfdcan1) != HAL_OK)
  {
    Error_Handler();
  }

}

static void MX_FDCAN2_Init(void)
{

  hfdcan2.Instance = FDCAN2;
  hfdcan2.Init.FrameFormat = FDCAN_FRAME_FD_BRS;
  hfdcan2.Init.Mode = FDCAN_MODE_NORMAL;
  hfdcan2.Init.AutoRetransmission = ENABLE;
  hfdcan2.Init.TransmitPause = ENABLE;
  hfdcan2.Init.ProtocolException = DISABLE;
  hfdcan2.Init.NominalPrescaler = 10;
  hfdcan2.Init.NominalSyncJumpWidth = 2;
  hfdcan2.Init.NominalTimeSeg1 = 5;
  hfdcan2.Init.NominalTimeSeg2 = 2;
  hfdcan2.Init.DataPrescaler = 1;
  hfdcan2.Init.DataSyncJumpWidth = 4;
  hfdcan2.Init.DataTimeSeg1 = 11;
  hfdcan2.Init.DataTimeSeg2 = 4;
  hfdcan2.Init.MessageRAMOffset = 1280;
  hfdcan2.Init.StdFiltersNbr = 28;
  hfdcan2.Init.ExtFiltersNbr = 0;
  hfdcan2.Init.RxFifo0ElmtsNbr = 20;
  hfdcan2.Init.RxFifo0ElmtSize = FDCAN_DATA_BYTES_64;
  hfdcan2.Init.RxFifo1ElmtsNbr = 0;
  hfdcan2.Init.RxFifo1ElmtSize = FDCAN_DATA_BYTES_64;
  hfdcan2.Init.RxBuffersNbr = 0;
  hfdcan2.Init.RxBufferSize = FDCAN_DATA_BYTES_64;
  hfdcan2.Init.TxEventsNbr = 0;
  hfdcan2.Init.TxBuffersNbr = 0;
  hfdcan2.Init.TxFifoQueueElmtsNbr = 32;
  hfdcan2.Init.TxFifoQueueMode = FDCAN_TX_QUEUE_OPERATION;
  hfdcan2.Init.TxElmtSize = FDCAN_DATA_BYTES_64;
  if (HAL_FDCAN_Init(&hfdcan2) != HAL_OK)
  {
    Error_Handler();
  }

}

static void MX_I2C1_Init(void)
{

  hi2c1.Instance = I2C1;
  hi2c1.Init.Timing = 0x307075B1;
  hi2c1.Init.OwnAddress1 = 0;
  hi2c1.Init.AddressingMode = I2C_ADDRESSINGMODE_7BIT;
  hi2c1.Init.DualAddressMode = I2C_DUALADDRESS_DISABLE;
  hi2c1.Init.OwnAddress2 = 0;
  hi2c1.Init.OwnAddress2Masks = I2C_OA2_NOMASK;
  hi2c1.Init.GeneralCallMode = I2C_GENERALCALL_DISABLE;
  hi2c1.Init.NoStretchMode = I2C_NOSTRETCH_DISABLE;
  if (HAL_I2C_Init(&hi2c1) != HAL_OK)
  {
    Error_Handler();
  }

  /** Configure Analogue filter
  */
  if (HAL_I2CEx_ConfigAnalogFilter(&hi2c1, I2C_ANALOGFILTER_ENABLE) != HAL_OK)
  {
    Error_Handler();
  }

  /** Configure Digital filter
  */
  if (HAL_I2CEx_ConfigDigitalFilter(&hi2c1, 0) != HAL_OK)
  {
    Error_Handler();
  }

}

static void MX_TIM2_Init(void)
{

  TIM_ClockConfigTypeDef sClockSourceConfig = {0};
  TIM_MasterConfigTypeDef sMasterConfig = {0};

  htim2.Instance = TIM2;
  htim2.Init.Prescaler = 240-1;
  htim2.Init.CounterMode = TIM_COUNTERMODE_UP;
  htim2.Init.Period = 100-1;
  htim2.Init.ClockDivision = TIM_CLOCKDIVISION_DIV1;
  htim2.Init.AutoReloadPreload = TIM_AUTORELOAD_PRELOAD_ENABLE;
  if (HAL_TIM_Base_Init(&htim2) != HAL_OK)
  {
    Error_Handler();
  }
  sClockSourceConfig.ClockSource = TIM_CLOCKSOURCE_INTERNAL;
  if (HAL_TIM_ConfigClockSource(&htim2, &sClockSourceConfig) != HAL_OK)
  {
    Error_Handler();
  }
  sMasterConfig.MasterOutputTrigger = TIM_TRGO_UPDATE;
  sMasterConfig.MasterSlaveMode = TIM_MASTERSLAVEMODE_DISABLE;
  if (HAL_TIMEx_MasterConfigSynchronization(&htim2, &sMasterConfig) != HAL_OK)
  {
    Error_Handler();
  }

}

static void MX_UART7_Init(void)
{

  huart7.Instance = UART7;
  huart7.Init.BaudRate = 921600;
  huart7.Init.WordLength = UART_WORDLENGTH_8B;
  huart7.Init.StopBits = UART_STOPBITS_1;
  huart7.Init.Parity = UART_PARITY_NONE;
  huart7.Init.Mode = UART_MODE_TX_RX;
  huart7.Init.HwFlowCtl = UART_HWCONTROL_NONE;
  huart7.Init.OverSampling = UART_OVERSAMPLING_16;
  huart7.Init.OneBitSampling = UART_ONE_BIT_SAMPLE_DISABLE;
  huart7.Init.ClockPrescaler = UART_PRESCALER_DIV1;
  huart7.AdvancedInit.AdvFeatureInit = UART_ADVFEATURE_NO_INIT;
  if (HAL_UART_Init(&huart7) != HAL_OK)
  {
    Error_Handler();
  }
  if (HAL_UARTEx_SetTxFifoThreshold(&huart7, UART_TXFIFO_THRESHOLD_1_4) != HAL_OK)
  {
    Error_Handler();
  }
  if (HAL_UARTEx_SetRxFifoThreshold(&huart7, UART_RXFIFO_THRESHOLD_1_4) != HAL_OK)
  {
    Error_Handler();
  }
  if (HAL_UARTEx_EnableFifoMode(&huart7) != HAL_OK)
  {
    Error_Handler();
  }

}

static void MX_UART8_Init(void)
{

  huart8.Instance = UART8;
  huart8.Init.BaudRate = 921600;
  huart8.Init.WordLength = UART_WORDLENGTH_8B;
  huart8.Init.StopBits = UART_STOPBITS_1;
  huart8.Init.Parity = UART_PARITY_NONE;
  huart8.Init.Mode = UART_MODE_TX_RX;
  huart8.Init.HwFlowCtl = UART_HWCONTROL_NONE;
  huart8.Init.OverSampling = UART_OVERSAMPLING_16;
  huart8.Init.OneBitSampling = UART_ONE_BIT_SAMPLE_DISABLE;
  huart8.Init.ClockPrescaler = UART_PRESCALER_DIV1;
  huart8.AdvancedInit.AdvFeatureInit = UART_ADVFEATURE_NO_INIT;
  if (HAL_UART_Init(&huart8) != HAL_OK)
  {
    Error_Handler();
  }
  if (HAL_UARTEx_SetTxFifoThreshold(&huart8, UART_TXFIFO_THRESHOLD_1_4) != HAL_OK)
  {
    Error_Handler();
  }
  if (HAL_UARTEx_SetRxFifoThreshold(&huart8, UART_RXFIFO_THRESHOLD_1_4) != HAL_OK)
  {
    Error_Handler();
  }
  if (HAL_UARTEx_EnableFifoMode(&huart8) != HAL_OK)
  {
    Error_Handler();
  }

}

static void MX_USB_OTG_FS_USB_Init(void)
{

}

static void MX_DMA_Init(void)
{

  /* DMA controller clock enable */
  __HAL_RCC_DMA1_CLK_ENABLE();

  /* DMA interrupt init */
  /* DMA1_Stream0_IRQn interrupt configuration */
  HAL_NVIC_SetPriority(DMA1_Stream0_IRQn, 5, 0);
  HAL_NVIC_EnableIRQ(DMA1_Stream0_IRQn);
  /* DMA1_Stream1_IRQn interrupt configuration */
  HAL_NVIC_SetPriority(DMA1_Stream1_IRQn, 5, 0);
  HAL_NVIC_EnableIRQ(DMA1_Stream1_IRQn);
  /* DMA1_Stream2_IRQn interrupt configuration */
  HAL_NVIC_SetPriority(DMA1_Stream2_IRQn, 5, 0);
  HAL_NVIC_EnableIRQ(DMA1_Stream2_IRQn);
  /* DMA1_Stream3_IRQn interrupt configuration */
  HAL_NVIC_SetPriority(DMA1_Stream3_IRQn, 5, 0);
  HAL_NVIC_EnableIRQ(DMA1_Stream3_IRQn);

}

static void MX_GPIO_Init(void)
{
  GPIO_InitTypeDef GPIO_InitStruct = {0};

  /* GPIO Ports Clock Enable */
  __HAL_RCC_GPIOG_CLK_ENABLE();
  __HAL_RCC_GPIOC_CLK_ENABLE();
  __HAL_RCC_GPIOE_CLK_ENABLE();
  __HAL_RCC_GPIOB_CLK_ENABLE();
  __HAL_RCC_GPIOD_CLK_ENABLE();
  __HAL_RCC_GPIOA_CLK_ENABLE();
  __HAL_RCC_GPIOF_CLK_ENABLE();
  __HAL_RCC_GPIOH_CLK_ENABLE();

  /*Configure GPIO pin Output Level */
  HAL_GPIO_WritePin(GPIOG, HMMG_PWR_EN_Pin|L_GRF_PWR_EN_Pin|R_GRF_PWR_EN_Pin|IMU_PWR_EN_Pin
                          |FES_PWR_EN_Pin|EMG_PWR_EN_Pin, GPIO_PIN_RESET);

  /*Configure GPIO pin Output Level */
  HAL_GPIO_WritePin(GPIOD, USB_PWR_ON_Pin|TP12_Pin, GPIO_PIN_RESET);

  /*Configure GPIO pin Output Level */
  HAL_GPIO_WritePin(EXT_PWR_EN_GPIO_Port, EXT_PWR_EN_Pin, GPIO_PIN_RESET);

  /*Configure GPIO pin Output Level */
  HAL_GPIO_WritePin(GPIOB, FUNC_LED_2_Pin|FUNC_LED_1_Pin|FUNC_LED_3_Pin, GPIO_PIN_RESET);

  /*Configure GPIO pin Output Level */
  HAL_GPIO_WritePin(GPIOC, CM_LED_G_Pin|CM_LED_B_Pin|CM_LED_R_Pin|POWER_ON_LED_Pin, GPIO_PIN_RESET);

  /*Configure GPIO pin Output Level */
  HAL_GPIO_WritePin(GPIOA, TP11_Pin|TP5_Pin|TP9_Pin|TP10_Pin
                          |TP7_Pin|TP8_Pin, GPIO_PIN_RESET);

  /*Configure GPIO pins : HMMG_PWR_EN_Pin L_GRF_PWR_EN_Pin R_GRF_PWR_EN_Pin IMU_PWR_EN_Pin
                           FES_PWR_EN_Pin EMG_PWR_EN_Pin */
  GPIO_InitStruct.Pin = HMMG_PWR_EN_Pin|L_GRF_PWR_EN_Pin|R_GRF_PWR_EN_Pin|IMU_PWR_EN_Pin
                          |FES_PWR_EN_Pin|EMG_PWR_EN_Pin;
  GPIO_InitStruct.Mode = GPIO_MODE_OUTPUT_PP;
  GPIO_InitStruct.Pull = GPIO_NOPULL;
  GPIO_InitStruct.Speed = GPIO_SPEED_FREQ_LOW;
  HAL_GPIO_Init(GPIOG, &GPIO_InitStruct);

  /*Configure GPIO pins : IMU__FAULT_Pin HMMG__FAULT_Pin R_GRF__FAULT_Pin L_GRF__FAULT_Pin
                           FES__FAULT_Pin EMG__FAULT_Pin HWREV_2_Pin HWREV_1_Pin */
  GPIO_InitStruct.Pin = IMU__FAULT_Pin|HMMG__FAULT_Pin|R_GRF__FAULT_Pin|L_GRF__FAULT_Pin
                          |FES__FAULT_Pin|EMG__FAULT_Pin|HWREV_2_Pin|HWREV_1_Pin;
  GPIO_InitStruct.Mode = GPIO_MODE_INPUT;
  GPIO_InitStruct.Pull = GPIO_NOPULL;
  HAL_GPIO_Init(GPIOG, &GPIO_InitStruct);

  /*Configure GPIO pins : FUNC_BTN_1_Pin FUNC_BTN_2_Pin FUNC_BTN_3_Pin */
  GPIO_InitStruct.Pin = FUNC_BTN_1_Pin|FUNC_BTN_2_Pin|FUNC_BTN_3_Pin;
  GPIO_InitStruct.Mode = GPIO_MODE_INPUT;
  GPIO_InitStruct.Pull = GPIO_NOPULL;
  HAL_GPIO_Init(GPIOC, &GPIO_InitStruct);

  /*Configure GPIO pin : USB_PWR_ON_Pin */
  GPIO_InitStruct.Pin = USB_PWR_ON_Pin;
  GPIO_InitStruct.Mode = GPIO_MODE_OUTPUT_PP;
  GPIO_InitStruct.Pull = GPIO_PULLUP;
  GPIO_InitStruct.Speed = GPIO_SPEED_FREQ_VERY_HIGH;
  HAL_GPIO_Init(USB_PWR_ON_GPIO_Port, &GPIO_InitStruct);

  /*Configure GPIO pin : EXT_PWR_EN_Pin */
  GPIO_InitStruct.Pin = EXT_PWR_EN_Pin;
  GPIO_InitStruct.Mode = GPIO_MODE_OUTPUT_PP;
  GPIO_InitStruct.Pull = GPIO_NOPULL;
  GPIO_InitStruct.Speed = GPIO_SPEED_FREQ_LOW;
  HAL_GPIO_Init(EXT_PWR_EN_GPIO_Port, &GPIO_InitStruct);

  /*Configure GPIO pins : FUNC_LED_2_Pin FUNC_LED_1_Pin FUNC_LED_3_Pin */
  GPIO_InitStruct.Pin = FUNC_LED_2_Pin|FUNC_LED_1_Pin|FUNC_LED_3_Pin;
  GPIO_InitStruct.Mode = GPIO_MODE_OUTPUT_PP;
  GPIO_InitStruct.Pull = GPIO_NOPULL;
  GPIO_InitStruct.Speed = GPIO_SPEED_FREQ_LOW;
  HAL_GPIO_Init(GPIOB, &GPIO_InitStruct);

  /*Configure GPIO pin : TP12_Pin */
  GPIO_InitStruct.Pin = TP12_Pin;
  GPIO_InitStruct.Mode = GPIO_MODE_OUTPUT_PP;
  GPIO_InitStruct.Pull = GPIO_PULLDOWN;
  GPIO_InitStruct.Speed = GPIO_SPEED_FREQ_LOW;
  HAL_GPIO_Init(TP12_GPIO_Port, &GPIO_InitStruct);

  /*Configure GPIO pin : USB_OTG_UFP_ID_Pin */
  GPIO_InitStruct.Pin = USB_OTG_UFP_ID_Pin;
  GPIO_InitStruct.Mode = GPIO_MODE_AF_PP;
  GPIO_InitStruct.Pull = GPIO_NOPULL;
  GPIO_InitStruct.Speed = GPIO_SPEED_FREQ_LOW;
  GPIO_InitStruct.Alternate = GPIO_AF10_OTG1_FS;
  HAL_GPIO_Init(USB_OTG_UFP_ID_GPIO_Port, &GPIO_InitStruct);

  /*Configure GPIO pin : USB_OTG_FS_VBUS_Pin */
  GPIO_InitStruct.Pin = USB_OTG_FS_VBUS_Pin;
  GPIO_InitStruct.Mode = GPIO_MODE_INPUT;
  GPIO_InitStruct.Pull = GPIO_PULLUP;
  HAL_GPIO_Init(USB_OTG_FS_VBUS_GPIO_Port, &GPIO_InitStruct);

  /*Configure GPIO pins : CM_LED_G_Pin CM_LED_B_Pin CM_LED_R_Pin POWER_ON_LED_Pin */
  GPIO_InitStruct.Pin = CM_LED_G_Pin|CM_LED_B_Pin|CM_LED_R_Pin|POWER_ON_LED_Pin;
  GPIO_InitStruct.Mode = GPIO_MODE_OUTPUT_PP;
  GPIO_InitStruct.Pull = GPIO_NOPULL;
  GPIO_InitStruct.Speed = GPIO_SPEED_FREQ_LOW;
  HAL_GPIO_Init(GPIOC, &GPIO_InitStruct);

  /*Configure GPIO pins : TP11_Pin TP5_Pin TP9_Pin TP10_Pin
                           TP7_Pin */
  GPIO_InitStruct.Pin = TP11_Pin|TP5_Pin|TP9_Pin|TP10_Pin
                          |TP7_Pin;
  GPIO_InitStruct.Mode = GPIO_MODE_OUTPUT_PP;
  GPIO_InitStruct.Pull = GPIO_PULLDOWN;
  GPIO_InitStruct.Speed = GPIO_SPEED_FREQ_LOW;
  HAL_GPIO_Init(GPIOA, &GPIO_InitStruct);

  /*Configure GPIO pins : USB_OTG_FS_DP_Pin USB_OTG_FS_DM_Pin */
  GPIO_InitStruct.Pin = USB_OTG_FS_DP_Pin|USB_OTG_FS_DM_Pin;
  GPIO_InitStruct.Mode = GPIO_MODE_AF_PP;
  GPIO_InitStruct.Pull = GPIO_NOPULL;
  GPIO_InitStruct.Speed = GPIO_SPEED_FREQ_VERY_HIGH;
  GPIO_InitStruct.Alternate = GPIO_AF10_OTG1_FS;
  HAL_GPIO_Init(GPIOA, &GPIO_InitStruct);

  /*Configure GPIO pins : EXT_GPIO_1_Pin EXT_GPIO_3_Pin EXT_GPIO_2_Pin EXT_GPIO_4_Pin
                           EXT_GPIO_5_Pin EXT_GPIO_6_Pin EXT_GPIO_8_Pin EXT_GPIO_7_Pin */
  GPIO_InitStruct.Pin = EXT_GPIO_1_Pin|EXT_GPIO_3_Pin|EXT_GPIO_2_Pin|EXT_GPIO_4_Pin
                          |EXT_GPIO_5_Pin|EXT_GPIO_6_Pin|EXT_GPIO_8_Pin|EXT_GPIO_7_Pin;
  GPIO_InitStruct.Mode = GPIO_MODE_INPUT;
  GPIO_InitStruct.Pull = GPIO_NOPULL;
  HAL_GPIO_Init(GPIOF, &GPIO_InitStruct);

  /*Configure GPIO pin : USB_OC__DET_Pin */
  GPIO_InitStruct.Pin = USB_OC__DET_Pin;
  GPIO_InitStruct.Mode = GPIO_MODE_INPUT;
  GPIO_InitStruct.Pull = GPIO_NOPULL;
  HAL_GPIO_Init(USB_OC__DET_GPIO_Port, &GPIO_InitStruct);

  /*Configure GPIO pin : TP8_Pin */
  GPIO_InitStruct.Pin = TP8_Pin;
  GPIO_InitStruct.Mode = GPIO_MODE_OUTPUT_PP;
  GPIO_InitStruct.Pull = GPIO_NOPULL;
  GPIO_InitStruct.Speed = GPIO_SPEED_FREQ_LOW;
  HAL_GPIO_Init(TP8_GPIO_Port, &GPIO_InitStruct);

  /*Configure GPIO pin : HWREV_0_Pin */
  GPIO_InitStruct.Pin = HWREV_0_Pin;
  GPIO_InitStruct.Mode = GPIO_MODE_INPUT;
  GPIO_InitStruct.Pull = GPIO_NOPULL;
  HAL_GPIO_Init(HWREV_0_GPIO_Port, &GPIO_InitStruct);

}

void StartDefaultTask(void *argument)
{
  for(;;)
  {
    osDelay(1);
  }
}

__weak void StartUserTask(void *argument)
{
  for(;;)
  {
    osDelay(1);
  }
}

__weak void StartStartupTask(void *argument)
{
  for(;;)
  {
    osDelay(1);
  }
}

 /* MPU Configuration */

void MPU_Config(void)
{
  MPU_Region_InitTypeDef MPU_InitStruct = {0};

  /* Disables the MPU */
  HAL_MPU_Disable();

  /** Initializes and configures the Region and the memory to be protected
  */
  MPU_InitStruct.Enable = MPU_REGION_ENABLE;
  MPU_InitStruct.Number = MPU_REGION_NUMBER0;
  MPU_InitStruct.BaseAddress = 0x30000000;
  MPU_InitStruct.Size = MPU_REGION_SIZE_256KB;
  MPU_InitStruct.SubRegionDisable = 0x0;
  MPU_InitStruct.TypeExtField = MPU_TEX_LEVEL1;
  MPU_InitStruct.AccessPermission = MPU_REGION_FULL_ACCESS;
  MPU_InitStruct.DisableExec = MPU_INSTRUCTION_ACCESS_DISABLE;
  MPU_InitStruct.IsShareable = MPU_ACCESS_SHAREABLE;
  MPU_InitStruct.IsCacheable = MPU_ACCESS_NOT_CACHEABLE;
  MPU_InitStruct.IsBufferable = MPU_ACCESS_NOT_BUFFERABLE;

  HAL_MPU_ConfigRegion(&MPU_InitStruct);

  /** Initializes and configures the Region and the memory to be protected
  */
  MPU_InitStruct.Number = MPU_REGION_NUMBER1;
  MPU_InitStruct.BaseAddress = 0x30040000;
  MPU_InitStruct.Size = MPU_REGION_SIZE_32KB;

  HAL_MPU_ConfigRegion(&MPU_InitStruct);

  /** Initializes and configures the Region and the memory to be protected
  */
  MPU_InitStruct.Number = MPU_REGION_NUMBER2;
  MPU_InitStruct.BaseAddress = 0x38000000;
  MPU_InitStruct.Size = MPU_REGION_SIZE_64KB;

  HAL_MPU_ConfigRegion(&MPU_InitStruct);
  /* Enables the MPU */
  HAL_MPU_Enable(MPU_HFNMI_PRIVDEF);

}

void HAL_TIM_PeriodElapsedCallback(TIM_HandleTypeDef *htim)
{
  if (htim->Instance == TIM1)
  {
    HAL_IncTick();
  }
}

void Error_Handler(void)
{
  /* USER CODE BEGIN Error_Handler_Debug */
  /* [?��?��]
   * ?�� 명령?���??? 추�??���??? 코드�??? ?�� 줄에 ?��?��?��?�� 즉시
   * ?��버거�??? ?��?��?���??? 멈춥?��?��. (Breakpoint?? ?��?��)
   */
  __BKPT(0); // <--- ?�� 줄을 추�??��?��?��.
  /* User can add his own implementation to report the HAL error return state */
  __disable_irq();
  while (1)
  {
  }
  /* USER CODE END Error_Handler_Debug */
}
